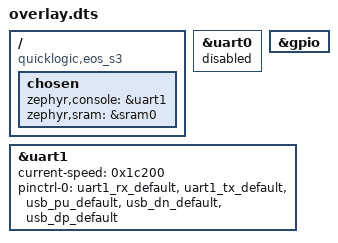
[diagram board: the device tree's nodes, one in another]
/ {
	compatible = "quicklogic,eos_s3";
	chosen {
		zephyr,console = &uart1;
		zephyr,sram = &sram0;
	};
};
&uart0{
	status = "disabled";
};
&gpio{
	status = "okay";
};
&uart1{
	status = "okay";
	current-speed = < 0x1c200 >;
	pinctrl-0 = < &uart1_rx_default &uart1_tx_default &usb_pu_default &usb_dn_default &usb_dp_default >;
	pinctrl-names = "default";
};
